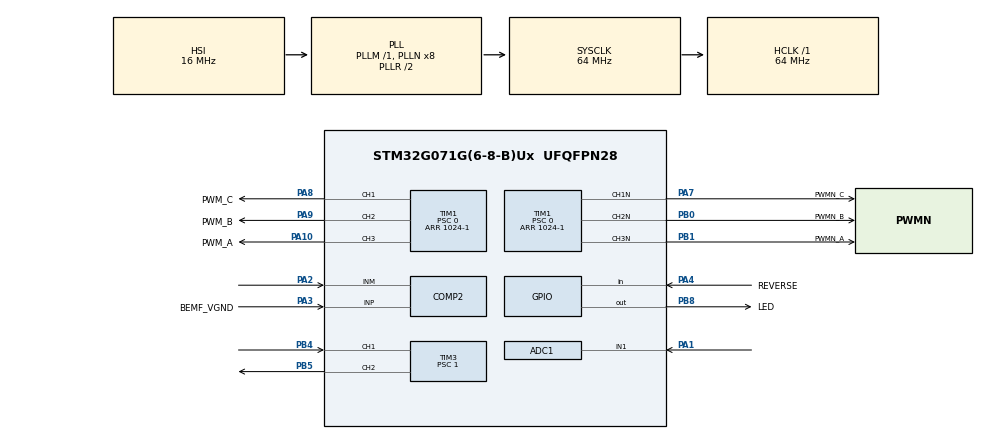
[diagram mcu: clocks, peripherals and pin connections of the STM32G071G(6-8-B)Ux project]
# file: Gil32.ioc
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ADC1.Channel-0\#ChannelRegularConversion=ADC_CHANNEL_1
ADC1.NbrOfConversionFlag=1
ADC1.Rank-0\#ChannelRegularConversion=1
ADC1.SamplingTime-0\#ChannelRegularConversion=ADC_SAMPLINGTIME_COMMON_1
ADC1.SelectedChannel=ADC_CHANNEL_1
ADC1.master=1
COMP2.BlankingSrce=COMP_BLANKINGSRC_TIM1_OC5
COMP2.Hysteresis=COMP_HYSTERESIS_HIGH
COMP2.Mode=COMP_POWERMODE_MEDIUMSPEED
COMP2.TriggerMode=COMP_TRIGGERMODE_IT_RISING
Dma.Request0=TIM3_CH1
Dma.Request1=TIM1_CH3
Dma.Request2=TIM1_CH2
Dma.Request3=TIM1_CH1
Dma.Request4=TIM3_CH2
Dma.TIM1_CH1.3.Direction=DMA_MEMORY_TO_PERIPH
Dma.TIM1_CH1.3.EventEnable=DISABLE
Dma.TIM1_CH1.3.Instance=DMA1_Channel1
Dma.TIM1_CH1.3.MemDataAlignment=DMA_MDATAALIGN_HALFWORD
Dma.TIM1_CH1.3.MemInc=DMA_MINC_ENABLE
Dma.TIM1_CH1.3.Mode=DMA_CIRCULAR
Dma.TIM1_CH1.3.PeriphDataAlignment=DMA_PDATAALIGN_HALFWORD
Dma.TIM1_CH1.3.PeriphInc=DMA_PINC_DISABLE
Dma.TIM1_CH1.3.Polarity=HAL_DMAMUX_REQ_GEN_RISING
Dma.TIM1_CH1.3.Priority=DMA_PRIORITY_HIGH
Dma.TIM1_CH1.3.RequestNumber=1
Dma.TIM1_CH1.3.SignalID=NONE
Dma.TIM1_CH1.3.SyncEnable=DISABLE
Dma.TIM1_CH1.3.SyncPolarity=HAL_DMAMUX_SYNC_NO_EVENT
Dma.TIM1_CH1.3.SyncRequestNumber=1
Dma.TIM1_CH1.3.SyncSignalID=NONE
Dma.TIM1_CH2.2.Direction=DMA_MEMORY_TO_PERIPH
Dma.TIM1_CH2.2.EventEnable=DISABLE
Dma.TIM1_CH2.2.Instance=DMA1_Channel2
Dma.TIM1_CH2.2.MemDataAlignment=DMA_MDATAALIGN_HALFWORD
Dma.TIM1_CH2.2.MemInc=DMA_MINC_ENABLE
Dma.TIM1_CH2.2.Mode=DMA_CIRCULAR
Dma.TIM1_CH2.2.PeriphDataAlignment=DMA_PDATAALIGN_HALFWORD
Dma.TIM1_CH2.2.PeriphInc=DMA_PINC_DISABLE
Dma.TIM1_CH2.2.Polarity=HAL_DMAMUX_REQ_GEN_RISING
Dma.TIM1_CH2.2.Priority=DMA_PRIORITY_HIGH
Dma.TIM1_CH2.2.RequestNumber=1
Dma.TIM1_CH2.2.SignalID=NONE
Dma.TIM1_CH2.2.SyncEnable=DISABLE
Dma.TIM1_CH2.2.SyncPolarity=HAL_DMAMUX_SYNC_NO_EVENT
Dma.TIM1_CH2.2.SyncRequestNumber=1
Dma.TIM1_CH2.2.SyncSignalID=NONE
Dma.TIM1_CH3.1.Direction=DMA_MEMORY_TO_PERIPH
Dma.TIM1_CH3.1.EventEnable=DISABLE
Dma.TIM1_CH3.1.Instance=DMA1_Channel3
Dma.TIM1_CH3.1.MemDataAlignment=DMA_MDATAALIGN_HALFWORD
Dma.TIM1_CH3.1.MemInc=DMA_MINC_ENABLE
Dma.TIM1_CH3.1.Mode=DMA_CIRCULAR
Dma.TIM1_CH3.1.PeriphDataAlignment=DMA_PDATAALIGN_HALFWORD
Dma.TIM1_CH3.1.PeriphInc=DMA_PINC_DISABLE
Dma.TIM1_CH3.1.Polarity=HAL_DMAMUX_REQ_GEN_RISING
Dma.TIM1_CH3.1.Priority=DMA_PRIORITY_HIGH
Dma.TIM1_CH3.1.RequestNumber=1
Dma.TIM1_CH3.1.SignalID=NONE
Dma.TIM1_CH3.1.SyncEnable=DISABLE
Dma.TIM1_CH3.1.SyncPolarity=HAL_DMAMUX_SYNC_NO_EVENT
Dma.TIM1_CH3.1.SyncRequestNumber=1
Dma.TIM1_CH3.1.SyncSignalID=NONE
Dma.TIM3_CH1.0.Direction=DMA_PERIPH_TO_MEMORY
Dma.TIM3_CH1.0.EventEnable=DISABLE
Dma.TIM3_CH1.0.Instance=DMA1_Channel5
Dma.TIM3_CH1.0.MemDataAlignment=DMA_MDATAALIGN_HALFWORD
Dma.TIM3_CH1.0.MemInc=DMA_MINC_ENABLE
Dma.TIM3_CH1.0.Mode=DMA_NORMAL
Dma.TIM3_CH1.0.PeriphDataAlignment=DMA_PDATAALIGN_HALFWORD
Dma.TIM3_CH1.0.PeriphInc=DMA_PINC_DISABLE
Dma.TIM3_CH1.0.Polarity=HAL_DMAMUX_REQ_GEN_RISING
Dma.TIM3_CH1.0.Priority=DMA_PRIORITY_VERY_HIGH
Dma.TIM3_CH1.0.RequestNumber=1
Dma.TIM3_CH1.0.SignalID=NONE
Dma.TIM3_CH1.0.SyncEnable=DISABLE
Dma.TIM3_CH1.0.SyncPolarity=HAL_DMAMUX_SYNC_NO_EVENT
Dma.TIM3_CH1.0.SyncRequestNumber=1
Dma.TIM3_CH1.0.SyncSignalID=NONE
Dma.TIM3_CH2.4.Direction=DMA_MEMORY_TO_PERIPH
Dma.TIM3_CH2.4.EventEnable=DISABLE
Dma.TIM3_CH2.4.Instance=DMA1_Channel4
Dma.TIM3_CH2.4.MemDataAlignment=DMA_MDATAALIGN_HALFWORD
Dma.TIM3_CH2.4.MemInc=DMA_MINC_ENABLE
Dma.TIM3_CH2.4.Mode=DMA_NORMAL
Dma.TIM3_CH2.4.PeriphDataAlignment=DMA_PDATAALIGN_HALFWORD
Dma.TIM3_CH2.4.PeriphInc=DMA_PINC_DISABLE
Dma.TIM3_CH2.4.Polarity=HAL_DMAMUX_REQ_GEN_RISING
Dma.TIM3_CH2.4.Priority=DMA_PRIORITY_LOW
Dma.TIM3_CH2.4.RequestNumber=1
Dma.TIM3_CH2.4.SignalID=NONE
Dma.TIM3_CH2.4.SyncEnable=DISABLE
Dma.TIM3_CH2.4.SyncPolarity=HAL_DMAMUX_SYNC_NO_EVENT
Dma.TIM3_CH2.4.SyncRequestNumber=1
Dma.TIM3_CH2.4.SyncSignalID=NONE
Mcu.Family=STM32G0
Mcu.Name=STM32G071G(6-8-B)Ux
Mcu.Package=UFQFPN28
NVIC.ADC1_COMP_IRQn=true\:0\:0\:false\:false\:true\:false\:true\:true
NVIC.DMA1_Ch4_7_DMAMUX1_OVR_IRQn=true\:0\:0\:false\:false\:true\:true\:true\:true
NVIC.DMA1_Channel2_3_IRQn=true\:0\:0\:false\:false\:true\:true\:true\:true
NVIC.TIM17_IRQn=true\:0\:0\:false\:false\:true\:true\:true\:true
NVIC.TIM3_IRQn=true\:0\:0\:true\:false\:true\:true\:true\:true
PA1.Mode=IN1
PA1.Signal=ADC1_IN1
PA10\ [PA12].GPIO_Label=PWM_A
PA10\ [PA12].GPIO_PuPd=GPIO_NOPULL
PA10\ [PA12].GPIO_Speed=GPIO_SPEED_FREQ_VERY_HIGH
PA10\ [PA12].Signal=S_TIM1_CH3
PA13.Mode=Serial_Wire
PA13.Signal=SYS_SWDIO
PA14-BOOT0.Mode=Serial_Wire
PA14-BOOT0.Signal=SYS_SWCLK
PA2.Mode=INM
PA2.Signal=COMP2_INM
PA3.GPIO_Label=BEMF_VGND
PA3.Mode=INP
PA3.Signal=COMP2_INP
PA4.GPIO_Label=REVERSE
PA4.Signal=GPIO_Input
PA7.GPIO_Label=PWMN_C
PA7.GPIO_PuPd=GPIO_NOPULL
PA7.GPIO_Speed=GPIO_SPEED_FREQ_VERY_HIGH
PA7.Mode=PWM Generation1 CH1 CH1N
PA7.Signal=TIM1_CH1N
PA8.GPIO_Label=PWM_C
PA8.GPIO_PuPd=GPIO_NOPULL
PA8.GPIO_Speed=GPIO_SPEED_FREQ_VERY_HIGH
PA8.PinState=GPIO_PIN_RESET
PA8.Signal=S_TIM1_CH1
PA9\ [PA11].GPIO_Label=PWM_B
PA9\ [PA11].GPIO_PuPd=GPIO_NOPULL
PA9\ [PA11].GPIO_Speed=GPIO_SPEED_FREQ_VERY_HIGH
PA9\ [PA11].Signal=S_TIM1_CH2
PB0.GPIO_Label=PWMN_B
PB0.GPIO_PuPd=GPIO_NOPULL
PB0.GPIO_Speed=GPIO_SPEED_FREQ_VERY_HIGH
PB0.Mode=PWM Generation2 CH2 CH2N
PB0.Signal=TIM1_CH2N
PB1.GPIO_Label=PWMN_A
PB1.GPIO_PuPd=GPIO_NOPULL
PB1.GPIO_Speed=GPIO_SPEED_FREQ_VERY_HIGH
PB1.Mode=PWM Generation3 CH3 CH3N
PB1.Signal=TIM1_CH3N
PB4.Signal=S_TIM3_CH1
PB5.Signal=S_TIM3_CH2
PB8.GPIO_Label=LED
PB8.Signal=GPIO_Output
ProjectManager.HeapSize=0x200
ProjectManager.StackSize=0x400
ProjectManager.TargetToolchain=STM32CubeIDE
RCC.ADCFreq_Value=64000000
RCC.AHBFreq_Value=64000000
RCC.CortexFreq_Value=64000000
RCC.EXTERNAL_CLOCK_VALUE=48000
RCC.HCLKFreq_Value=64000000
RCC.HSE_VALUE=8000000
RCC.HSI_VALUE=16000000
RCC.LSE_VALUE=32768
RCC.PLLQ=RCC_PLLQ_DIV4
RCC.SYSCLKFreq_VALUE=64000000
RCC.SYSCLKSource=RCC_SYSCLKSOURCE_PLLCLK
RCC.VCOOutputFreq_Value=128000000
SH.S_TIM1_CH1.0=TIM1_CH1,PWM Generation1 CH1 CH1N
SH.S_TIM1_CH2.0=TIM1_CH2,PWM Generation2 CH2 CH2N
SH.S_TIM1_CH3.0=TIM1_CH3,PWM Generation3 CH3 CH3N
SH.S_TIM3_CH1.0=TIM3_CH1,Input_Capture1_from_TI1
SH.S_TIM3_CH2.0=TIM3_CH2,PWM Generation2 CH2
TIM1.AutoReloadPreload=TIM_AUTORELOAD_PRELOAD_ENABLE
TIM1.Channel-PWM\ Generation1\ CH1\ CH1N=TIM_CHANNEL_1
TIM1.Channel-PWM\ Generation2\ CH2\ CH2N=TIM_CHANNEL_2
TIM1.Channel-PWM\ Generation3\ CH3\ CH3N=TIM_CHANNEL_3
TIM1.Channel-PWM\ Generation5\ No\ Output=TIM_CHANNEL_5
TIM1.CounterMode=TIM_COUNTERMODE_UP
TIM1.DeadTime=0
TIM1.OC1Preload_PWM=DISABLE
TIM1.OC2Preload_PWM=DISABLE
TIM1.OC3Preload_PWM=DISABLE
TIM1.OC5Preload_PWM=DISABLE
TIM1.Period=1024-1
TIM1.Prescaler=0
TIM1.Pulse-PWM\ Generation5\ No\ Output=0
TIM17.AutoReloadPreload=TIM_AUTORELOAD_PRELOAD_ENABLE
TIM17.Channel=TIM_CHANNEL_1
TIM17.Period=50
TIM17.Prescaler=64000-1
TIM3.AutoReloadPreload=TIM_AUTORELOAD_PRELOAD_DISABLE
TIM3.Channel-Input_Capture1_from_TI1=TIM_CHANNEL_1
TIM3.Channel-Output\ Compare4\ No\ Output=TIM_CHANNEL_4
TIM3.Channel-PWM\ Generation2\ CH2=TIM_CHANNEL_2
TIM3.ICPolarity_CH1=TIM_INPUTCHANNELPOLARITY_BOTHEDGE
TIM3.OC2Preload_PWM=DISABLE
TIM3.OC4Preload=ENABLE
TIM3.OCPolarity_2=TIM_OCPOLARITY_LOW
TIM3.OCPolarity_4=TIM_OCPOLARITY_HIGH
TIM3.Prescaler=1
TIM6.AutoReloadPreload=TIM_AUTORELOAD_PRELOAD_ENABLE
TIM6.Prescaler=64
TIM7.AutoReloadPreload=TIM_AUTORELOAD_PRELOAD_ENABLE
VP_SYS_VS_PINREMAP.Mode=PINREMAP
VP_SYS_VS_PINREMAP_10_12.Mode=PINREMAP_10_12
VP_TIM17_VS_ClockSourceINT.Mode=Enable_Timer
VP_TIM17_VS_no_output1.Mode=Output Compare1 No Output
VP_TIM1_VS_no_output5.Mode=PWM Generation5 No Output
VP_TIM3_VS_no_output4.Mode=Output Compare4 No Output
VP_TIM6_VS_ClockSourceINT.Mode=Enable_Timer
VP_TIM7_VS_ClockSourceINT.Mode=Enable_Timer
board=custom

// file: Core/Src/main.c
/* USER CODE BEGIN Header */
/**
  ******************************************************************************
  * @file           : main.c
  * @brief          : Main program body
  ******************************************************************************
  * @attention
  *
  * Copyright (c) 2024 STMicroelectronics.
  * All rights reserved.
  *
  * This software is licensed under terms that can be found in the LICENSE file
  * in the root directory of this software component.
  * If no LICENSE file comes with this software, it is provided AS-IS.
  *
  ******************************************************************************
  */
/* USER CODE END Header */
#include "main.h"

ADC_HandleTypeDef hadc1;

COMP_HandleTypeDef hcomp2;

TIM_HandleTypeDef htim1;
TIM_HandleTypeDef htim3;
TIM_HandleTypeDef htim6;
TIM_HandleTypeDef htim7;
TIM_HandleTypeDef htim17;
DMA_HandleTypeDef hdma_tim1_ch3;
DMA_HandleTypeDef hdma_tim1_ch2;
DMA_HandleTypeDef hdma_tim1_ch1;
DMA_HandleTypeDef hdma_tim3_ch1;
DMA_HandleTypeDef hdma_tim3_ch2;

void SystemClock_Config(void);
static void MX_GPIO_Init(void);
static void MX_DMA_Init(void);
static void MX_TIM3_Init(void);
static void MX_COMP2_Init(void);
static void MX_TIM1_Init(void);
static void MX_ADC1_Init(void);
static void MX_TIM7_Init(void);
static void MX_TIM17_Init(void);
static void MX_TIM6_Init(void);

int main(void)
{

  /* MCU Configuration--------------------------------------------------------*/

  /* Reset of all peripherals, Initializes the Flash interface and the Systick. */
  HAL_Init();

  /* Configure the system clock */
  SystemClock_Config();

  /* Initialize all configured peripherals */
  MX_GPIO_Init();
  MX_DMA_Init();
  MX_TIM3_Init();
  MX_COMP2_Init();
  MX_TIM1_Init();
  MX_ADC1_Init();
  MX_TIM7_Init();
  MX_TIM17_Init();
  MX_TIM6_Init();

  /* Infinite loop */
  /* USER CODE BEGIN WHILE */
  maincpp();
  while (1)
  {
    /* USER CODE END WHILE */

  }
}

void SystemClock_Config(void)
{
  RCC_OscInitTypeDef RCC_OscInitStruct = {0};
  RCC_ClkInitTypeDef RCC_ClkInitStruct = {0};

  /** Configure the main internal regulator output voltage
  */
  HAL_PWREx_ControlVoltageScaling(PWR_REGULATOR_VOLTAGE_SCALE1);

  /** Initializes the RCC Oscillators according to the specified parameters
  * in the RCC_OscInitTypeDef structure.
  */
  RCC_OscInitStruct.OscillatorType = RCC_OSCILLATORTYPE_HSI;
  RCC_OscInitStruct.HSIState = RCC_HSI_ON;
  RCC_OscInitStruct.HSIDiv = RCC_HSI_DIV1;
  RCC_OscInitStruct.HSICalibrationValue = RCC_HSICALIBRATION_DEFAULT;
  RCC_OscInitStruct.PLL.PLLState = RCC_PLL_ON;
  RCC_OscInitStruct.PLL.PLLSource = RCC_PLLSOURCE_HSI;
  RCC_OscInitStruct.PLL.PLLM = RCC_PLLM_DIV1;
  RCC_OscInitStruct.PLL.PLLN = 8;
  RCC_OscInitStruct.PLL.PLLP = RCC_PLLP_DIV2;
  RCC_OscInitStruct.PLL.PLLQ = RCC_PLLQ_DIV4;
  RCC_OscInitStruct.PLL.PLLR = RCC_PLLR_DIV2;
  if (HAL_RCC_OscConfig(&RCC_OscInitStruct) != HAL_OK)
  {
    Error_Handler();
  }

  /** Initializes the CPU, AHB and APB buses clocks
  */
  RCC_ClkInitStruct.ClockType = RCC_CLOCKTYPE_HCLK|RCC_CLOCKTYPE_SYSCLK
                              |RCC_CLOCKTYPE_PCLK1;
  RCC_ClkInitStruct.SYSCLKSource = RCC_SYSCLKSOURCE_PLLCLK;
  RCC_ClkInitStruct.AHBCLKDivider = RCC_SYSCLK_DIV1;
  RCC_ClkInitStruct.APB1CLKDivider = RCC_HCLK_DIV1;

  if (HAL_RCC_ClockConfig(&RCC_ClkInitStruct, FLASH_LATENCY_2) != HAL_OK)
  {
    Error_Handler();
  }
}

static void MX_ADC1_Init(void)
{

  ADC_ChannelConfTypeDef sConfig = {0};

  /** Configure the global features of the ADC (Clock, Resolution, Data Alignment and number of conversion)
  */
  hadc1.Instance = ADC1;
  hadc1.Init.ClockPrescaler = ADC_CLOCK_SYNC_PCLK_DIV2;
  hadc1.Init.Resolution = ADC_RESOLUTION_12B;
  hadc1.Init.DataAlign = ADC_DATAALIGN_RIGHT;
  hadc1.Init.ScanConvMode = ADC_SCAN_DISABLE;
  hadc1.Init.EOCSelection = ADC_EOC_SINGLE_CONV;
  hadc1.Init.LowPowerAutoWait = DISABLE;
  hadc1.Init.LowPowerAutoPowerOff = DISABLE;
  hadc1.Init.ContinuousConvMode = DISABLE;
  hadc1.Init.NbrOfConversion = 1;
  hadc1.Init.DiscontinuousConvMode = DISABLE;
  hadc1.Init.ExternalTrigConv = ADC_SOFTWARE_START;
  hadc1.Init.ExternalTrigConvEdge = ADC_EXTERNALTRIGCONVEDGE_NONE;
  hadc1.Init.DMAContinuousRequests = DISABLE;
  hadc1.Init.Overrun = ADC_OVR_DATA_PRESERVED;
  hadc1.Init.SamplingTimeCommon1 = ADC_SAMPLETIME_1CYCLE_5;
  hadc1.Init.SamplingTimeCommon2 = ADC_SAMPLETIME_1CYCLE_5;
  hadc1.Init.OversamplingMode = DISABLE;
  hadc1.Init.TriggerFrequencyMode = ADC_TRIGGER_FREQ_HIGH;
  if (HAL_ADC_Init(&hadc1) != HAL_OK)
  {
    Error_Handler();
  }

  /** Configure Regular Channel
  */
  sConfig.Channel = ADC_CHANNEL_1;
  sConfig.Rank = ADC_REGULAR_RANK_1;
  sConfig.SamplingTime = ADC_SAMPLINGTIME_COMMON_1;
  if (HAL_ADC_ConfigChannel(&hadc1, &sConfig) != HAL_OK)
  {
    Error_Handler();
  }

}

static void MX_COMP2_Init(void)
{

  hcomp2.Instance = COMP2;
  hcomp2.Init.InputPlus = COMP_INPUT_PLUS_IO3;
  hcomp2.Init.InputMinus = COMP_INPUT_MINUS_IO3;
  hcomp2.Init.OutputPol = COMP_OUTPUTPOL_NONINVERTED;
  hcomp2.Init.WindowOutput = COMP_WINDOWOUTPUT_EACH_COMP;
  hcomp2.Init.Hysteresis = COMP_HYSTERESIS_HIGH;
  hcomp2.Init.BlankingSrce = COMP_BLANKINGSRC_TIM1_OC5;
  hcomp2.Init.Mode = COMP_POWERMODE_MEDIUMSPEED;
  hcomp2.Init.WindowMode = COMP_WINDOWMODE_DISABLE;
  hcomp2.Init.TriggerMode = COMP_TRIGGERMODE_IT_RISING;
  if (HAL_COMP_Init(&hcomp2) != HAL_OK)
  {
    Error_Handler();
  }

}

static void MX_TIM1_Init(void)
{

  TIM_MasterConfigTypeDef sMasterConfig = {0};
  TIM_OC_InitTypeDef sConfigOC = {0};
  TIM_BreakDeadTimeConfigTypeDef sBreakDeadTimeConfig = {0};

  htim1.Instance = TIM1;
  htim1.Init.Prescaler = 0;
  htim1.Init.CounterMode = TIM_COUNTERMODE_UP;
  htim1.Init.Period = 1024-1;
  htim1.Init.ClockDivision = TIM_CLOCKDIVISION_DIV1;
  htim1.Init.RepetitionCounter = 0;
  htim1.Init.AutoReloadPreload = TIM_AUTORELOAD_PRELOAD_ENABLE;
  if (HAL_TIM_PWM_Init(&htim1) != HAL_OK)
  {
    Error_Handler();
  }
  sMasterConfig.MasterOutputTrigger = TIM_TRGO_RESET;
  sMasterConfig.MasterOutputTrigger2 = TIM_TRGO2_RESET;
  sMasterConfig.MasterSlaveMode = TIM_MASTERSLAVEMODE_DISABLE;
  if (HAL_TIMEx_MasterConfigSynchronization(&htim1, &sMasterConfig) != HAL_OK)
  {
    Error_Handler();
  }
  sConfigOC.OCMode = TIM_OCMODE_PWM1;
  sConfigOC.Pulse = 0;
  sConfigOC.OCPolarity = TIM_OCPOLARITY_HIGH;
  sConfigOC.OCNPolarity = TIM_OCNPOLARITY_HIGH;
  sConfigOC.OCFastMode = TIM_OCFAST_DISABLE;
  sConfigOC.OCIdleState = TIM_OCIDLESTATE_RESET;
  sConfigOC.OCNIdleState = TIM_OCNIDLESTATE_RESET;
  if (HAL_TIM_PWM_ConfigChannel(&htim1, &sConfigOC, TIM_CHANNEL_1) != HAL_OK)
  {
    Error_Handler();
  }
  __HAL_TIM_DISABLE_OCxPRELOAD(&htim1, TIM_CHANNEL_1);
  if (HAL_TIM_PWM_ConfigChannel(&htim1, &sConfigOC, TIM_CHANNEL_2) != HAL_OK)
  {
    Error_Handler();
  }
  __HAL_TIM_DISABLE_OCxPRELOAD(&htim1, TIM_CHANNEL_2);
  if (HAL_TIM_PWM_ConfigChannel(&htim1, &sConfigOC, TIM_CHANNEL_3) != HAL_OK)
  {
    Error_Handler();
  }
  __HAL_TIM_DISABLE_OCxPRELOAD(&htim1, TIM_CHANNEL_3);
  if (HAL_TIM_PWM_ConfigChannel(&htim1, &sConfigOC, TIM_CHANNEL_5) != HAL_OK)
  {
    Error_Handler();
  }
  __HAL_TIM_DISABLE_OCxPRELOAD(&htim1, TIM_CHANNEL_5);
  sBreakDeadTimeConfig.OffStateRunMode = TIM_OSSR_DISABLE;
  sBreakDeadTimeConfig.OffStateIDLEMode = TIM_OSSI_DISABLE;
  sBreakDeadTimeConfig.LockLevel = TIM_LOCKLEVEL_OFF;
  sBreakDeadTimeConfig.DeadTime = 0;
  sBreakDeadTimeConfig.BreakState = TIM_BREAK_DISABLE;
  sBreakDeadTimeConfig.BreakPolarity = TIM_BREAKPOLARITY_HIGH;
  sBreakDeadTimeConfig.BreakFilter = 0;
  sBreakDeadTimeConfig.BreakAFMode = TIM_BREAK_AFMODE_INPUT;
  sBreakDeadTimeConfig.Break2State = TIM_BREAK2_DISABLE;
  sBreakDeadTimeConfig.Break2Polarity = TIM_BREAK2POLARITY_HIGH;
  sBreakDeadTimeConfig.Break2Filter = 0;
  sBreakDeadTimeConfig.Break2AFMode = TIM_BREAK_AFMODE_INPUT;
  sBreakDeadTimeConfig.AutomaticOutput = TIM_AUTOMATICOUTPUT_DISABLE;
  if (HAL_TIMEx_ConfigBreakDeadTime(&htim1, &sBreakDeadTimeConfig) != HAL_OK)
  {
    Error_Handler();
  }
  HAL_TIM_MspPostInit(&htim1);

}

static void MX_TIM3_Init(void)
{

  TIM_MasterConfigTypeDef sMasterConfig = {0};
  TIM_IC_InitTypeDef sConfigIC = {0};
  TIM_OC_InitTypeDef sConfigOC = {0};

  htim3.Instance = TIM3;
  htim3.Init.Prescaler = 1;
  htim3.Init.CounterMode = TIM_COUNTERMODE_UP;
  htim3.Init.Period = 65535;
  htim3.Init.ClockDivision = TIM_CLOCKDIVISION_DIV1;
  htim3.Init.AutoReloadPreload = TIM_AUTORELOAD_PRELOAD_DISABLE;
  if (HAL_TIM_IC_Init(&htim3) != HAL_OK)
  {
    Error_Handler();
  }
  if (HAL_TIM_PWM_Init(&htim3) != HAL_OK)
  {
    Error_Handler();
  }
  if (HAL_TIM_OC_Init(&htim3) != HAL_OK)
  {
    Error_Handler();
  }
  sMasterConfig.MasterOutputTrigger = TIM_TRGO_RESET;
  sMasterConfig.MasterSlaveMode = TIM_MASTERSLAVEMODE_DISABLE;
  if (HAL_TIMEx_MasterConfigSynchronization(&htim3, &sMasterConfig) != HAL_OK)
  {
    Error_Handler();
  }
  sConfigIC.ICPolarity = TIM_INPUTCHANNELPOLARITY_BOTHEDGE;
  sConfigIC.ICSelection = TIM_ICSELECTION_DIRECTTI;
  sConfigIC.ICPrescaler = TIM_ICPSC_DIV1;
  sConfigIC.ICFilter = 0;
  if (HAL_TIM_IC_ConfigChannel(&htim3, &sConfigIC, TIM_CHANNEL_1) != HAL_OK)
  {
    Error_Handler();
  }
  sConfigOC.OCMode = TIM_OCMODE_PWM1;
  sConfigOC.Pulse = 0;
  sConfigOC.OCPolarity = TIM_OCPOLARITY_LOW;
  sConfigOC.OCFastMode = TIM_OCFAST_DISABLE;
  if (HAL_TIM_PWM_ConfigChannel(&htim3, &sConfigOC, TIM_CHANNEL_2) != HAL_OK)
  {
    Error_Handler();
  }
  __HAL_TIM_DISABLE_OCxPRELOAD(&htim3, TIM_CHANNEL_2);
  sConfigOC.OCMode = TIM_OCMODE_TIMING;
  sConfigOC.OCPolarity = TIM_OCPOLARITY_HIGH;
  if (HAL_TIM_OC_ConfigChannel(&htim3, &sConfigOC, TIM_CHANNEL_4) != HAL_OK)
  {
    Error_Handler();
  }
  __HAL_TIM_ENABLE_OCxPRELOAD(&htim3, TIM_CHANNEL_4);
  HAL_TIM_MspPostInit(&htim3);

}

static void MX_TIM6_Init(void)
{

  TIM_MasterConfigTypeDef sMasterConfig = {0};

  htim6.Instance = TIM6;
  htim6.Init.Prescaler = 64;
  htim6.Init.CounterMode = TIM_COUNTERMODE_UP;
  htim6.Init.Period = 65535;
  htim6.Init.AutoReloadPreload = TIM_AUTORELOAD_PRELOAD_ENABLE;
  if (HAL_TIM_Base_Init(&htim6) != HAL_OK)
  {
    Error_Handler();
  }
  sMasterConfig.MasterOutputTrigger = TIM_TRGO_RESET;
  sMasterConfig.MasterSlaveMode = TIM_MASTERSLAVEMODE_DISABLE;
  if (HAL_TIMEx_MasterConfigSynchronization(&htim6, &sMasterConfig) != HAL_OK)
  {
    Error_Handler();
  }

}

static void MX_TIM7_Init(void)
{

  TIM_MasterConfigTypeDef sMasterConfig = {0};

  htim7.Instance = TIM7;
  htim7.Init.Prescaler = 0;
  htim7.Init.CounterMode = TIM_COUNTERMODE_UP;
  htim7.Init.Period = 65535;
  htim7.Init.AutoReloadPreload = TIM_AUTORELOAD_PRELOAD_ENABLE;
  if (HAL_TIM_Base_Init(&htim7) != HAL_OK)
  {
    Error_Handler();
  }
  sMasterConfig.MasterOutputTrigger = TIM_TRGO_RESET;
  sMasterConfig.MasterSlaveMode = TIM_MASTERSLAVEMODE_DISABLE;
  if (HAL_TIMEx_MasterConfigSynchronization(&htim7, &sMasterConfig) != HAL_OK)
  {
    Error_Handler();
  }

}

static void MX_TIM17_Init(void)
{

  TIM_OC_InitTypeDef sConfigOC = {0};
  TIM_BreakDeadTimeConfigTypeDef sBreakDeadTimeConfig = {0};

  htim17.Instance = TIM17;
  htim17.Init.Prescaler = 64000-1;
  htim17.Init.CounterMode = TIM_COUNTERMODE_UP;
  htim17.Init.Period = 50;
  htim17.Init.ClockDivision = TIM_CLOCKDIVISION_DIV1;
  htim17.Init.RepetitionCounter = 0;
  htim17.Init.AutoReloadPreload = TIM_AUTORELOAD_PRELOAD_ENABLE;
  if (HAL_TIM_Base_Init(&htim17) != HAL_OK)
  {
    Error_Handler();
  }
  if (HAL_TIM_OC_Init(&htim17) != HAL_OK)
  {
    Error_Handler();
  }
  sConfigOC.OCMode = TIM_OCMODE_TIMING;
  sConfigOC.Pulse = 0;
  sConfigOC.OCPolarity = TIM_OCPOLARITY_HIGH;
  sConfigOC.OCNPolarity = TIM_OCNPOLARITY_HIGH;
  sConfigOC.OCFastMode = TIM_OCFAST_DISABLE;
  sConfigOC.OCIdleState = TIM_OCIDLESTATE_RESET;
  sConfigOC.OCNIdleState = TIM_OCNIDLESTATE_RESET;
  if (HAL_TIM_OC_ConfigChannel(&htim17, &sConfigOC, TIM_CHANNEL_1) != HAL_OK)
  {
    Error_Handler();
  }
  sBreakDeadTimeConfig.OffStateRunMode = TIM_OSSR_DISABLE;
  sBreakDeadTimeConfig.OffStateIDLEMode = TIM_OSSI_DISABLE;
  sBreakDeadTimeConfig.LockLevel = TIM_LOCKLEVEL_OFF;
  sBreakDeadTimeConfig.DeadTime = 0;
  sBreakDeadTimeConfig.BreakState = TIM_BREAK_DISABLE;
  sBreakDeadTimeConfig.BreakPolarity = TIM_BREAKPOLARITY_HIGH;
  sBreakDeadTimeConfig.BreakFilter = 0;
  sBreakDeadTimeConfig.AutomaticOutput = TIM_AUTOMATICOUTPUT_DISABLE;
  if (HAL_TIMEx_ConfigBreakDeadTime(&htim17, &sBreakDeadTimeConfig) != HAL_OK)
  {
    Error_Handler();
  }

}

static void MX_DMA_Init(void)
{

  /* DMA controller clock enable */
  __HAL_RCC_DMA1_CLK_ENABLE();

  /* DMA interrupt init */
  /* DMA1_Channel2_3_IRQn interrupt configuration */
  HAL_NVIC_SetPriority(DMA1_Channel2_3_IRQn, 0, 0);
  HAL_NVIC_EnableIRQ(DMA1_Channel2_3_IRQn);
  /* DMA1_Ch4_7_DMAMUX1_OVR_IRQn interrupt configuration */
  HAL_NVIC_SetPriority(DMA1_Ch4_7_DMAMUX1_OVR_IRQn, 0, 0);
  HAL_NVIC_EnableIRQ(DMA1_Ch4_7_DMAMUX1_OVR_IRQn);

}

static void MX_GPIO_Init(void)
{
  GPIO_InitTypeDef GPIO_InitStruct = {0};

  /* GPIO Ports Clock Enable */
  __HAL_RCC_GPIOA_CLK_ENABLE();
  __HAL_RCC_GPIOB_CLK_ENABLE();

  /*Configure GPIO pin Output Level */
  HAL_GPIO_WritePin(LED_GPIO_Port, LED_Pin, GPIO_PIN_RESET);

  /*Configure GPIO pin : REVERSE_Pin */
  GPIO_InitStruct.Pin = REVERSE_Pin;
  GPIO_InitStruct.Mode = GPIO_MODE_INPUT;
  GPIO_InitStruct.Pull = GPIO_NOPULL;
  HAL_GPIO_Init(REVERSE_GPIO_Port, &GPIO_InitStruct);

  /*Configure GPIO pin : LED_Pin */
  GPIO_InitStruct.Pin = LED_Pin;
  GPIO_InitStruct.Mode = GPIO_MODE_OUTPUT_PP;
  GPIO_InitStruct.Pull = GPIO_NOPULL;
  GPIO_InitStruct.Speed = GPIO_SPEED_FREQ_LOW;
  HAL_GPIO_Init(LED_GPIO_Port, &GPIO_InitStruct);

}

void Error_Handler(void)
{
  __disable_irq();
  while (1)
  {
  }
}
